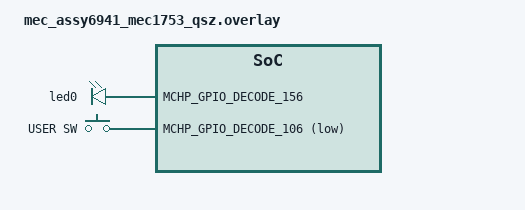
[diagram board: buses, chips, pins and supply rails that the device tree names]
/*
 * Copyright (c) 2026 Microchip Technology Inc
 *
 * SPDX-License-Identifier: Apache-2.0
 */

/ {
	aliases {
		led0 = &led0;
		sw0 = &button0;
	};

	leds {
		compatible = "gpio-leds";

		led0: led_0 {
			gpios = <MCHP_GPIO_DECODE_156 GPIO_ACTIVE_HIGH>;
		};
	};

	buttons {
		compatible = "gpio-keys";

		button0: button_0 {
			gpios = <MCHP_GPIO_DECODE_106 (GPIO_PULL_UP | GPIO_ACTIVE_LOW)>;
			label = "USER SW";
		};
	};
};
